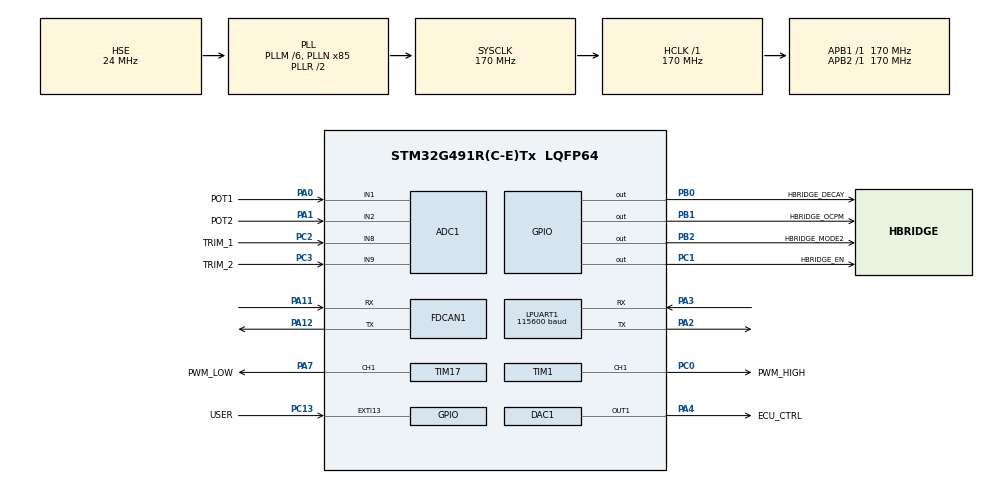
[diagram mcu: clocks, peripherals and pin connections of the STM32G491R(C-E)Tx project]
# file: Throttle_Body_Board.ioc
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ADC1.Channel-0\#ChannelRegularConversion=ADC_CHANNEL_1
ADC1.Channel-1\#ChannelRegularConversion=ADC_CHANNEL_2
ADC1.Channel-2\#ChannelRegularConversion=ADC_CHANNEL_8
ADC1.Channel-3\#ChannelRegularConversion=ADC_CHANNEL_9
ADC1.ContinuousConvMode=ENABLE
ADC1.DMAContinuousRequests=ENABLE
ADC1.NbrOfConversion=4
ADC1.NbrOfConversionFlag=1
ADC1.OffsetNumber-0\#ChannelRegularConversion=ADC_OFFSET_NONE
ADC1.OffsetNumber-1\#ChannelRegularConversion=ADC_OFFSET_NONE
ADC1.OffsetNumber-2\#ChannelRegularConversion=ADC_OFFSET_NONE
ADC1.OffsetNumber-3\#ChannelRegularConversion=ADC_OFFSET_NONE
ADC1.OversamplingMode=ENABLE
ADC1.Rank-0\#ChannelRegularConversion=1
ADC1.Rank-1\#ChannelRegularConversion=2
ADC1.Rank-2\#ChannelRegularConversion=3
ADC1.Rank-3\#ChannelRegularConversion=4
ADC1.Ratio=ADC_OVERSAMPLING_RATIO_256
ADC1.RightBitShift=ADC_RIGHTBITSHIFT_8
ADC1.SamplingTime-0\#ChannelRegularConversion=ADC_SAMPLETIME_12CYCLES_5
ADC1.SamplingTime-1\#ChannelRegularConversion=ADC_SAMPLETIME_12CYCLES_5
ADC1.SamplingTime-2\#ChannelRegularConversion=ADC_SAMPLETIME_12CYCLES_5
ADC1.SamplingTime-3\#ChannelRegularConversion=ADC_SAMPLETIME_12CYCLES_5
ADC1.master=1
Dma.ADC1.0.Direction=DMA_PERIPH_TO_MEMORY
Dma.ADC1.0.EventEnable=DISABLE
Dma.ADC1.0.Instance=DMA1_Channel1
Dma.ADC1.0.MemDataAlignment=DMA_MDATAALIGN_WORD
Dma.ADC1.0.MemInc=DMA_MINC_ENABLE
Dma.ADC1.0.Mode=DMA_CIRCULAR
Dma.ADC1.0.PeriphDataAlignment=DMA_PDATAALIGN_WORD
Dma.ADC1.0.PeriphInc=DMA_PINC_DISABLE
Dma.ADC1.0.Polarity=HAL_DMAMUX_REQ_GEN_RISING
Dma.ADC1.0.Priority=DMA_PRIORITY_LOW
Dma.ADC1.0.RequestNumber=1
Dma.ADC1.0.SignalID=NONE
Dma.ADC1.0.SyncEnable=DISABLE
Dma.ADC1.0.SyncPolarity=HAL_DMAMUX_SYNC_NO_EVENT
Dma.ADC1.0.SyncRequestNumber=1
Dma.ADC1.0.SyncSignalID=NONE
Dma.Request0=ADC1
FDCAN1.AutoRetransmission=ENABLE
FDCAN1.CalculateBaudRateNominal=999999
FDCAN1.CalculateTimeBitNominal=1000
FDCAN1.CalculateTimeQuantumNominal=58.82352941176471
FDCAN1.NominalPrescaler=10
FDCAN1.NominalTimeSeg1=14
FDCAN1.NominalTimeSeg2=2
FDCAN1.StdFiltersNbr=1
LPUART1.BaudRate=115600
Mcu.Family=STM32G4
Mcu.Name=STM32G491R(C-E)Tx
Mcu.Package=LQFP64
NVIC.DMA1_Channel1_IRQn=true\:0\:0\:false\:false\:true\:false\:true\:true
NVIC.EXTI15_10_IRQn=true\:0\:0\:false\:false\:true\:true\:true\:true
NVIC.FDCAN1_IT0_IRQn=true\:0\:0\:false\:false\:true\:true\:true\:true
NVIC.PriorityGroup=NVIC_PRIORITYGROUP_4
NVIC.TIM2_IRQn=true\:15\:0\:false\:false\:true\:true\:true\:true
NVIC.TIM4_IRQn=true\:0\:0\:false\:false\:true\:true\:true\:true
PA0.GPIO_Label=POT1
PA0.Mode=IN1-Single-Ended
PA0.Signal=ADC1_IN1
PA1.GPIO_Label=POT2
PA1.Mode=IN2-Single-Ended
PA1.Signal=ADC1_IN2
PA11.Mode=FDCAN_Activate
PA11.Signal=FDCAN1_RX
PA12.Mode=FDCAN_Activate
PA12.Signal=FDCAN1_TX
PA13.Mode=JTAG_4_pins
PA13.Signal=SYS_JTMS-SWDIO
PA14.Mode=JTAG_4_pins
PA14.Signal=SYS_JTCK-SWCLK
PA15.Mode=JTAG_4_pins
PA15.Signal=SYS_JTDI
PA2.Mode=Asynchronous
PA2.Signal=LPUART1_TX
PA3.Mode=Asynchronous
PA3.Signal=LPUART1_RX
PA4.GPIO_Label=ECU_CTRL
PA4.Signal=COMP_DAC11_group
PA7.GPIO_Label=PWM_LOW
PA7.Signal=S_TIM17_CH1
PB0.GPIO_Label=HBRIDGE_DECAY
PB0.Signal=GPIO_Output
PB1.GPIO_Label=HBRIDGE_OCPM
PB1.Signal=GPIO_Output
PB2.GPIO_Label=HBRIDGE_MODE2
PB2.Signal=GPIO_Output
PB3.Mode=JTAG_4_pins
PB3.Signal=SYS_JTDO-SWO
PC0.GPIO_Label=PWM_HIGH
PC0.Signal=S_TIM1_CH1
PC1.GPIO_Label=HBRIDGE_EN
PC1.Signal=GPIO_Output
PC13.GPIO_Label=USER
PC13.GPIO_ModeDefaultEXTI=GPIO_MODE_IT_FALLING
PC13.GPIO_PuPd=GPIO_PULLDOWN
PC13.Signal=GPXTI13
PC14-OSC32_IN.Mode=LSE-External-Oscillator
PC14-OSC32_IN.Signal=RCC_OSC32_IN
PC15-OSC32_OUT.Mode=LSE-External-Oscillator
PC15-OSC32_OUT.Signal=RCC_OSC32_OUT
PC2.GPIO_Label=TRIM_1
PC2.Mode=IN8-Single-Ended
PC2.Signal=ADC1_IN8
PC3.GPIO_Label=TRIM_2
PC3.Mode=IN9-Single-Ended
PC3.Signal=ADC1_IN9
PF0-OSC_IN.Mode=HSE-External-Oscillator
PF0-OSC_IN.Signal=RCC_OSC_IN
PF1-OSC_OUT.Mode=HSE-External-Oscillator
PF1-OSC_OUT.Signal=RCC_OSC_OUT
ProjectManager.HeapSize=0x200
ProjectManager.StackSize=0x400
ProjectManager.TargetToolchain=STM32CubeIDE
RCC.ADC12Freq_Value=170000000
RCC.ADC345Freq_Value=170000000
RCC.AHBFreq_Value=170000000
RCC.APB1Freq_Value=170000000
RCC.APB1TimFreq_Value=170000000
RCC.APB2Freq_Value=170000000
RCC.APB2TimFreq_Value=170000000
RCC.CortexFreq_Value=170000000
RCC.EXTERNAL_CLOCK_VALUE=12288000
RCC.HCLKFreq_Value=170000000
RCC.HSE_VALUE=24000000
RCC.HSI48_VALUE=48000000
RCC.HSI_VALUE=16000000
RCC.PLLM=RCC_PLLM_DIV6
RCC.PLLN=85
RCC.PLLSourceVirtual=RCC_PLLSOURCE_HSE
RCC.SYSCLKFreq_VALUE=170000000
RCC.SYSCLKSource=RCC_SYSCLKSOURCE_PLLCLK
RCC.VCOOutputFreq_Value=340000000
SH.COMP_DAC11_group.0=DAC1_OUT1,DAC_OUT1
SH.S_TIM17_CH1.0=TIM17_CH1,PWM Generation1 CH1
SH.S_TIM1_CH1.0=TIM1_CH1,PWM Generation1 CH1
TIM1.AutoReloadPreload=TIM_AUTORELOAD_PRELOAD_ENABLE
TIM1.Channel-PWM\ Generation1\ CH1=TIM_CHANNEL_1
TIM1.PeriodNoDither=100
TIM1.Prescaler=335
TIM17.AutoReloadPreload=TIM_AUTORELOAD_PRELOAD_ENABLE
TIM17.Channel=TIM_CHANNEL_1
TIM17.PeriodNoDither=100
TIM17.Prescaler=335
TIM2.AutoReloadPreload=TIM_AUTORELOAD_PRELOAD_ENABLE
TIM2.PeriodNoDither=200-1
TIM2.Prescaler=168-1
TIM3.AutoReloadPreload=TIM_AUTORELOAD_PRELOAD_ENABLE
TIM3.PeriodNoDither=200-1
TIM3.Prescaler=168-1
TIM4.PeriodNoDither=9999
TIM4.Prescaler=16999
VP_RTC_VS_RTC_Activate.Mode=RTC_Enabled
VP_SYS_VS_DBSignals.Mode=DisableDeadBatterySignals
VP_TIM17_VS_ClockSourceINT.Mode=Enable_Timer
VP_TIM2_VS_ClockSourceINT.Mode=Internal
VP_TIM3_VS_ClockSourceINT.Mode=Internal
VP_TIM4_VS_ClockSourceINT.Mode=Internal
board=custom

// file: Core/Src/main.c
/* USER CODE BEGIN Header */
/**
  ******************************************************************************
  * @file           : main.c
  * @brief          : Main program body
  ******************************************************************************
  * @attention
  *
  * Copyright (c) 2025 STMicroelectronics.
  * All rights reserved.
  *
  * This software is licensed under terms that can be found in the LICENSE file
  * in the root directory of this software component.
  * If no LICENSE file comes with this software, it is provided AS-IS.
  *
  *	Pinout:
  *		PC0: PWM_HIGH -> pot+
  *		PC1: HBRIDGE_EN
  *		PA0: TPS - adc (DMA) -> pot2
  *		PA7: PWM_LOW -> pot-
  *
  ******************************************************************************
  */
/* USER CODE END Header */
#include "main.h"
#include "adc.h"
#include "dac.h"
#include "dma.h"
#include "fdcan.h"
#include "usart.h"
#include "rtc.h"
#include "tim.h"
#include "gpio.h"

/* USER CODE BEGIN Includes */
#include "alt_main.h"
/* USER CODE END Includes */

void SystemClock_Config(void);

/* USER CODE BEGIN 0 */

/* USER CODE BEGIN 0 */

/* USER CODE END 0 */

int main(void)
{

  /* MCU Configuration--------------------------------------------------------*/

  /* Reset of all peripherals, Initializes the Flash interface and the Systick. */
  HAL_Init();

  /* Configure the system clock */
  SystemClock_Config();

  HAL_Delay(500);

  /* Initialize all configured peripherals */
  MX_GPIO_Init();
  MX_DMA_Init();
  MX_ADC1_Init();
  MX_FDCAN1_Init();
  MX_LPUART1_UART_Init();
  MX_TIM3_Init();
  MX_TIM1_Init();
  MX_RTC_Init();
  MX_TIM2_Init();
  MX_TIM17_Init();
  MX_DAC1_Init();
  MX_TIM4_Init();
  /* USER CODE BEGIN 2 */
  alt_main();

  /* USER CODE END 2 */

  /* Infinite loop */
	while (1) {

	}
}

void SystemClock_Config(void)
{
  RCC_OscInitTypeDef RCC_OscInitStruct = {0};
  RCC_ClkInitTypeDef RCC_ClkInitStruct = {0};

  /** Configure the main internal regulator output voltage
  */
  HAL_PWREx_ControlVoltageScaling(PWR_REGULATOR_VOLTAGE_SCALE1_BOOST);

  /** Initializes the RCC Oscillators according to the specified parameters
  * in the RCC_OscInitTypeDef structure.
  */
  RCC_OscInitStruct.OscillatorType = RCC_OSCILLATORTYPE_LSI|RCC_OSCILLATORTYPE_HSE;
  RCC_OscInitStruct.HSEState = RCC_HSE_ON;
  RCC_OscInitStruct.LSIState = RCC_LSI_ON;
  RCC_OscInitStruct.PLL.PLLState = RCC_PLL_ON;
  RCC_OscInitStruct.PLL.PLLSource = RCC_PLLSOURCE_HSE;
  RCC_OscInitStruct.PLL.PLLM = RCC_PLLM_DIV6;
  RCC_OscInitStruct.PLL.PLLN = 85;
  RCC_OscInitStruct.PLL.PLLP = RCC_PLLP_DIV2;
  RCC_OscInitStruct.PLL.PLLQ = RCC_PLLQ_DIV2;
  RCC_OscInitStruct.PLL.PLLR = RCC_PLLR_DIV2;
  if (HAL_RCC_OscConfig(&RCC_OscInitStruct) != HAL_OK)
  {
    Error_Handler();
  }

  /** Initializes the CPU, AHB and APB buses clocks
  */
  RCC_ClkInitStruct.ClockType = RCC_CLOCKTYPE_HCLK|RCC_CLOCKTYPE_SYSCLK
                              |RCC_CLOCKTYPE_PCLK1|RCC_CLOCKTYPE_PCLK2;
  RCC_ClkInitStruct.SYSCLKSource = RCC_SYSCLKSOURCE_PLLCLK;
  RCC_ClkInitStruct.AHBCLKDivider = RCC_SYSCLK_DIV1;
  RCC_ClkInitStruct.APB1CLKDivider = RCC_HCLK_DIV1;
  RCC_ClkInitStruct.APB2CLKDivider = RCC_HCLK_DIV1;

  if (HAL_RCC_ClockConfig(&RCC_ClkInitStruct, FLASH_LATENCY_4) != HAL_OK)
  {
    Error_Handler();
  }
}

void Error_Handler(void)
{
  __disable_irq();
  while (1)
  {
  }
}
